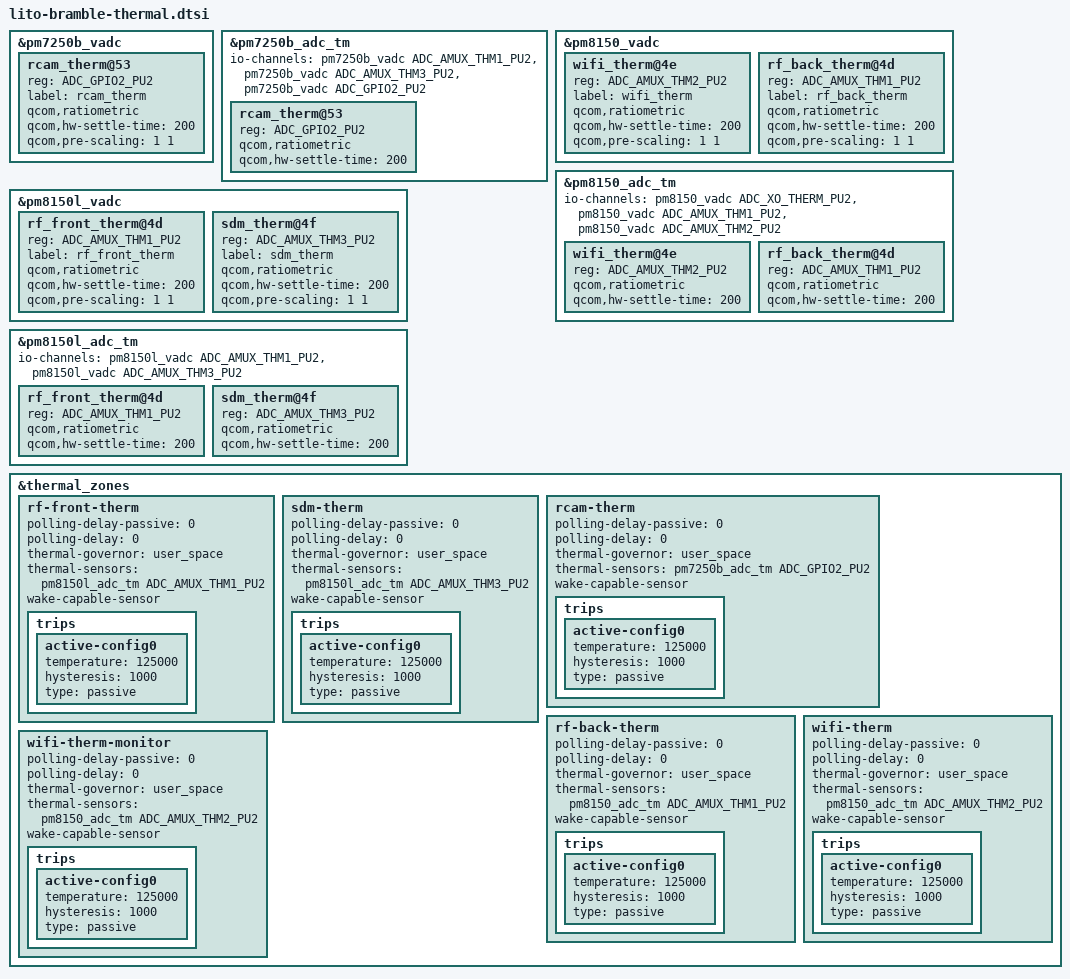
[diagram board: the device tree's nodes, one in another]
// SPDX-License-Identifier: GPL-2.0
/* Copyright (c) 2019, The Linux Foundation. All rights reserved.
 *
 * This program is free software; you can redistribute it and/or modify
 * it under the terms of the GNU General Public License version 2 and
 * only version 2 as published by the Free Software Foundation.
 *
 * This program is distributed in the hope that it will be useful,
 * but WITHOUT ANY WARRANTY; without even the implied warranty of
 * MERCHANTABILITY or FITNESS FOR A PARTICULAR PURPOSE.  See the
 * GNU General Public License for more details.
 */

&pm7250b_vadc {
	rcam_therm@53 {
		reg = <ADC_GPIO2_PU2>;
		label = "rcam_therm";
		qcom,ratiometric;
		qcom,hw-settle-time = <200>;
		qcom,pre-scaling = <1 1>;
	};
};

&pm7250b_adc_tm {
	io-channels = <&pm7250b_vadc ADC_AMUX_THM1_PU2>,
			<&pm7250b_vadc ADC_AMUX_THM3_PU2>,
			<&pm7250b_vadc ADC_GPIO2_PU2>;

	rcam_therm@53 {
		reg = <ADC_GPIO2_PU2>;
		qcom,ratiometric;
		qcom,hw-settle-time = <200>;
	};
};

&pm8150_vadc {
	wifi_therm@4e {
		reg = <ADC_AMUX_THM2_PU2>;
		label = "wifi_therm";
		qcom,ratiometric;
		qcom,hw-settle-time = <200>;
		qcom,pre-scaling = <1 1>;
	};

	rf_back_therm@4d {
		reg = <ADC_AMUX_THM1_PU2>;
		label = "rf_back_therm";
		qcom,ratiometric;
		qcom,hw-settle-time = <200>;
		qcom,pre-scaling = <1 1>;
	};
};

&pm8150_adc_tm {
	io-channels = <&pm8150_vadc ADC_XO_THERM_PU2>,
			<&pm8150_vadc ADC_AMUX_THM1_PU2>,
			<&pm8150_vadc ADC_AMUX_THM2_PU2>;

	wifi_therm@4e {
		reg = <ADC_AMUX_THM2_PU2>;
		qcom,ratiometric;
		qcom,hw-settle-time = <200>;
	};

	rf_back_therm@4d {
		reg = <ADC_AMUX_THM1_PU2>;
		qcom,ratiometric;
		qcom,hw-settle-time = <200>;
	};
};

&pm8150l_vadc {

	rf_front_therm@4d {
		reg = <ADC_AMUX_THM1_PU2>;
		label = "rf_front_therm";
		qcom,ratiometric;
		qcom,hw-settle-time = <200>;
		qcom,pre-scaling = <1 1>;
	};

	sdm_therm@4f {
		reg = <ADC_AMUX_THM3_PU2>;
		label = "sdm_therm";
		qcom,ratiometric;
		qcom,hw-settle-time = <200>;
		qcom,pre-scaling = <1 1>;
	};
};

&pm8150l_adc_tm {
	io-channels = <&pm8150l_vadc ADC_AMUX_THM1_PU2>,
			<&pm8150l_vadc ADC_AMUX_THM3_PU2>;

	/* Channel nodes */
	rf_front_therm@4d {
		reg = <ADC_AMUX_THM1_PU2>;
		qcom,ratiometric;
		qcom,hw-settle-time = <200>;
	};

	sdm_therm@4f {
		reg = <ADC_AMUX_THM3_PU2>;
		qcom,ratiometric;
		qcom,hw-settle-time = <200>;
	};
};

&thermal_zones {
	rf-front-therm {
		polling-delay-passive = <0>;
		polling-delay = <0>;
		thermal-governor = "user_space";
		thermal-sensors = <&pm8150l_adc_tm ADC_AMUX_THM1_PU2>;
		wake-capable-sensor;
		trips {
			active-config0 {
				temperature = <125000>;
				hysteresis = <1000>;
				type = "passive";
			};
		};
	};

	sdm-therm {
		polling-delay-passive = <0>;
		polling-delay = <0>;
		thermal-governor = "user_space";
		thermal-sensors = <&pm8150l_adc_tm ADC_AMUX_THM3_PU2>;
		wake-capable-sensor;
		trips {
			active-config0 {
				temperature = <125000>;
				hysteresis = <1000>;
				type = "passive";
			};
		};
	};

	rcam-therm {
		polling-delay-passive = <0>;
		polling-delay = <0>;
		thermal-governor = "user_space";
		thermal-sensors = <&pm7250b_adc_tm ADC_GPIO2_PU2>;
		wake-capable-sensor;
		trips {
			active-config0 {
				temperature = <125000>;
				hysteresis = <1000>;
				type = "passive";
			};
		};
	};

	rf-back-therm {
		polling-delay-passive = <0>;
		polling-delay = <0>;
		thermal-governor = "user_space";
		thermal-sensors = <&pm8150_adc_tm ADC_AMUX_THM1_PU2>;
		wake-capable-sensor;
		trips {
			active-config0 {
				temperature = <125000>;
				hysteresis = <1000>;
				type = "passive";
			};
		};
	};

	wifi-therm {
		polling-delay-passive = <0>;
		polling-delay = <0>;
		thermal-governor = "user_space";
		thermal-sensors = <&pm8150_adc_tm ADC_AMUX_THM2_PU2>;
		wake-capable-sensor;
		trips {
			active-config0 {
				temperature = <125000>;
				hysteresis = <1000>;
				type = "passive";
			};
		};
	};

	wifi-therm-monitor {
		polling-delay-passive = <0>;
		polling-delay = <0>;
		thermal-governor = "user_space";
		thermal-sensors = <&pm8150_adc_tm ADC_AMUX_THM2_PU2>;
		wake-capable-sensor;
		trips {
			active-config0 {
				temperature = <125000>;
				hysteresis = <1000>;
				type = "passive";
			};
		};
	};
};
